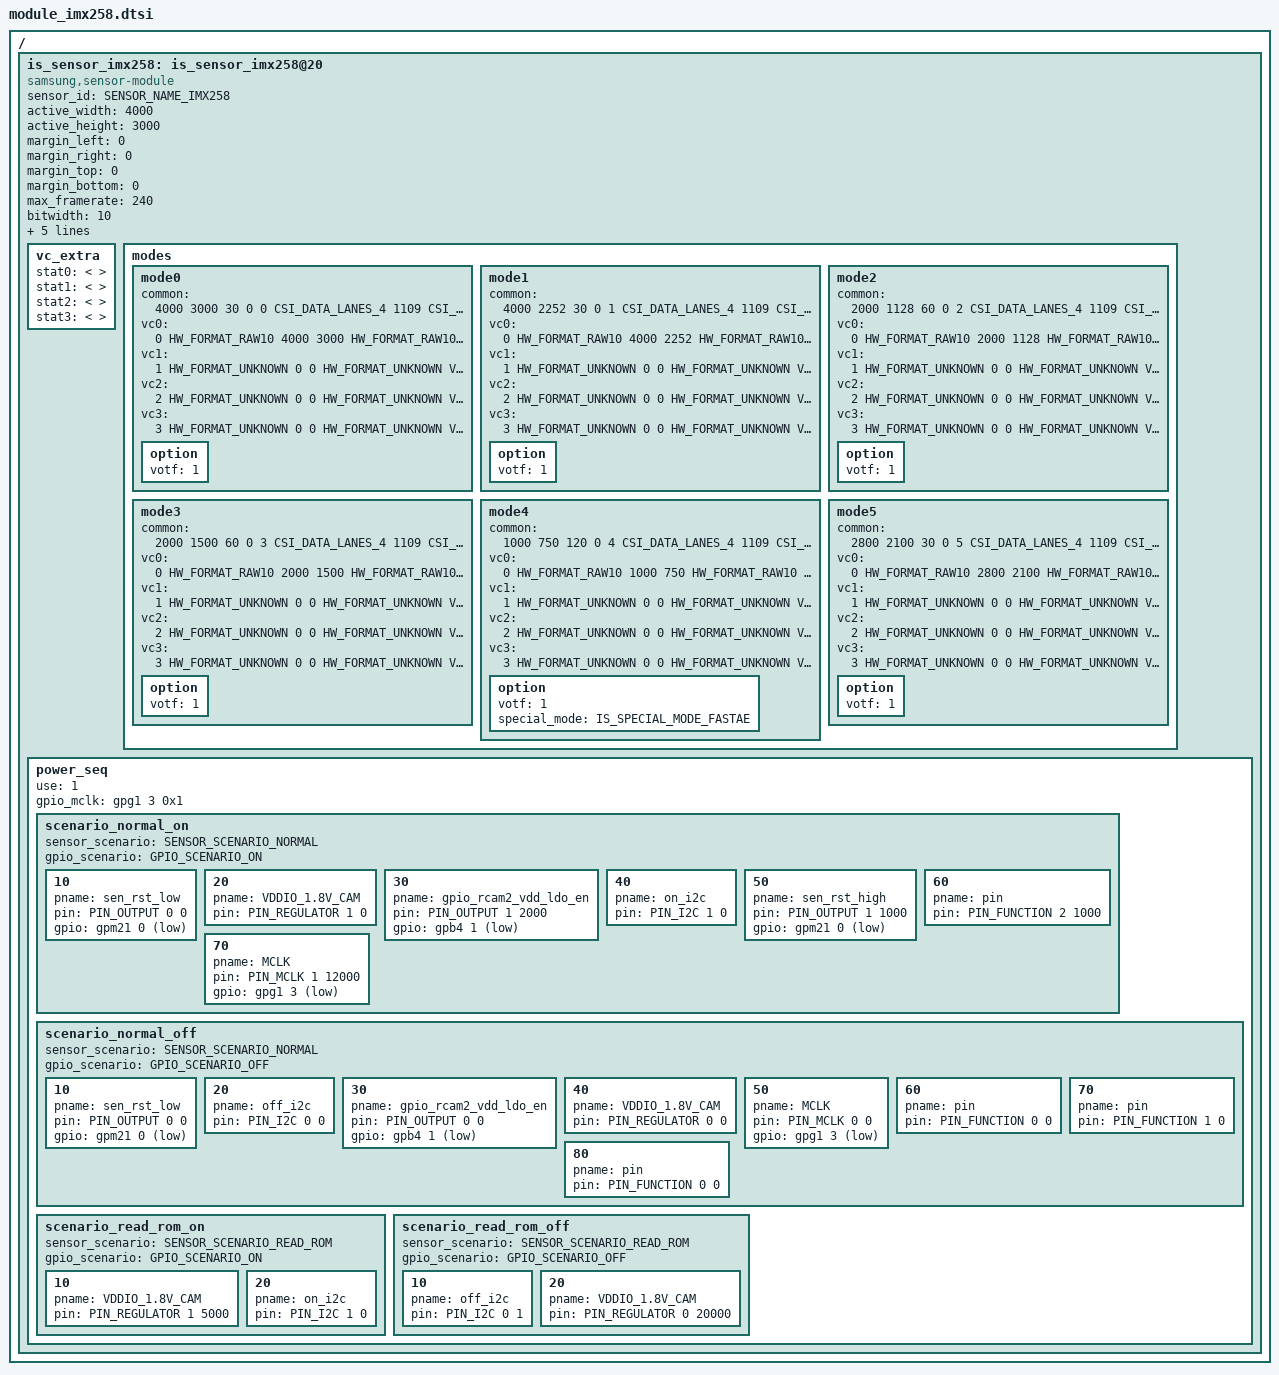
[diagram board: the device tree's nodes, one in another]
/*
 * SAMSUNG EXYNOSxxxx board camera device tree source
 *
 * Copyright (c) 2019 Samsung Electronics Co., Ltd.
 *		http://www.samsung.com
 *
 * This program is free software; you can redistribute it and/or modify
 * it under the terms of the GNU General Public License version 2 as
 * published by the Free Software Foundation.
 */

#include <dt-bindings/camera/exynos_is_dt.h>

/ {
	fragment@camera {
		target-path = "/";
		__overlay__ {
			is_sensor_imx258: is_sensor_imx258@20 {
				compatible = "samsung,sensor-module";

				/* common */
				sensor_id = <SENSOR_NAME_IMX258>;
				active_width = <4000>;
				active_height = <3000>;
				margin_left = <0>;
				margin_right = <0>;
				margin_top = <0>;
				margin_bottom = <0>;
				max_framerate = <240>;
				bitwidth = <10>;
				use_retention_mode = <SENSOR_RETENTION_UNSUPPORTED>;
				sensor_maker = "SONY";
				sensor_name = "IMX258";
				setfile_name = "setfile_imx258.bin";

				status = "okay";

				vc_extra {
					/* ex) statX = <stat_type, sensor_mode, max_width, max_height, max_element> */
					stat0 = </* not avaliable */>;	/* VC_BUF_DATA_TYPE_SENSOR_STAT1 */
					stat1 = </* not avaliable */>;	/* VC_BUF_DATA_TYPE_GENERAL_STAT1 */
					stat2 = </* not avaliable */>;	/* VC_BUF_DATA_TYPE_SENSOR_STAT2 */
					stat3 = </* not avaliable */>;	/* VC_BUF_DATA_TYPE_GENERAL_STAT2 */
				};

				/* sensor modes */
				modes {
					/* common = <width, height, fps, settle, mode, lane, speed, interleave, lrte, pd_mode> */
					/* vcX = <map, hwformat, width, height, hwformat, type, width, height> */
					mode0 {/* A-1 */
						common = <4000 3000 30 0 0 CSI_DATA_LANES_4 1109 CSI_MODE_VC_DT LRTE_DISABLE PD_NONE>;
						vc0 = </* in */ 0 HW_FORMAT_RAW10 4000 3000    /* out */ HW_FORMAT_RAW10 VC_NOTHING 4000 3000>;
						vc1 = </* in */ 1 HW_FORMAT_UNKNOWN 0 0        /* out */ HW_FORMAT_UNKNOWN VC_NOTHING 0 0>;
						vc2 = </* in */ 2 HW_FORMAT_UNKNOWN 0 0        /* out */ HW_FORMAT_UNKNOWN VC_NOTHING 0 0>;
						vc3 = </* in */ 3 HW_FORMAT_UNKNOWN 0 0        /* out */ HW_FORMAT_UNKNOWN VC_NOTHING 0 0>;
						option { votf = <1>; };
					};
					mode1 {/* N-1 */
						common = <4000 2252 30 0 1 CSI_DATA_LANES_4 1109 CSI_MODE_VC_DT LRTE_DISABLE PD_NONE>;
						vc0 = </* in */ 0 HW_FORMAT_RAW10 4000 2252    /* out */ HW_FORMAT_RAW10 VC_NOTHING 4000 2252>;
						vc1 = </* in */ 1 HW_FORMAT_UNKNOWN 0 0        /* out */ HW_FORMAT_UNKNOWN VC_NOTHING 0 0>;
						vc2 = </* in */ 2 HW_FORMAT_UNKNOWN 0 0        /* out */ HW_FORMAT_UNKNOWN VC_NOTHING 0 0>;
						vc3 = </* in */ 3 HW_FORMAT_UNKNOWN 0 0        /* out */ HW_FORMAT_UNKNOWN VC_NOTHING 0 0>;
						option { votf = <1>; };
					};
					mode2 {/* K-1 */
						common = <2000 1128 60 0 2 CSI_DATA_LANES_4 1109 CSI_MODE_VC_DT LRTE_DISABLE PD_NONE>;
						vc0 = </* in */ 0 HW_FORMAT_RAW10 2000 1128    /* out */ HW_FORMAT_RAW10 VC_NOTHING 2000 1128>;
						vc1 = </* in */ 1 HW_FORMAT_UNKNOWN 0 0        /* out */ HW_FORMAT_UNKNOWN VC_NOTHING 0 0>;
						vc2 = </* in */ 2 HW_FORMAT_UNKNOWN 0 0        /* out */ HW_FORMAT_UNKNOWN VC_NOTHING 0 0>;
						vc3 = </* in */ 3 HW_FORMAT_UNKNOWN 0 0        /* out */ HW_FORMAT_UNKNOWN VC_NOTHING 0 0>;
						option { votf = <1>; };
					};
					mode3 {/* J-1 */
						common = <2000 1500 60 0 3 CSI_DATA_LANES_4 1109 CSI_MODE_VC_DT LRTE_DISABLE PD_NONE>;
						vc0 = </* in */ 0 HW_FORMAT_RAW10 2000 1500    /* out */ HW_FORMAT_RAW10 VC_NOTHING 2000 1500>;
						vc1 = </* in */ 1 HW_FORMAT_UNKNOWN 0 0        /* out */ HW_FORMAT_UNKNOWN VC_NOTHING 0 0>;
						vc2 = </* in */ 2 HW_FORMAT_UNKNOWN 0 0        /* out */ HW_FORMAT_UNKNOWN VC_NOTHING 0 0>;
						vc3 = </* in */ 3 HW_FORMAT_UNKNOWN 0 0        /* out */ HW_FORMAT_UNKNOWN VC_NOTHING 0 0>;
						option { votf = <1>; };
					};
					mode4 {/* M-1 */
						common = <1000 750 120 0 4 CSI_DATA_LANES_4 1109 CSI_MODE_VC_DT LRTE_DISABLE PD_NONE>;
						vc0 = </* in */ 0 HW_FORMAT_RAW10 1000 750    /* out */ HW_FORMAT_RAW10 VC_NOTHING 1000 750>;
						vc1 = </* in */ 1 HW_FORMAT_UNKNOWN 0 0        /* out */ HW_FORMAT_UNKNOWN VC_NOTHING 0 0>;
						vc2 = </* in */ 2 HW_FORMAT_UNKNOWN 0 0        /* out */ HW_FORMAT_UNKNOWN VC_NOTHING 0 0>;
						vc3 = </* in */ 3 HW_FORMAT_UNKNOWN 0 0        /* out */ HW_FORMAT_UNKNOWN VC_NOTHING 0 0>;
						option { votf = <1>;  special_mode = <IS_SPECIAL_MODE_FASTAE>; };
					};
					mode5 {/* P-1 */
						common = <2800 2100 30 0 5 CSI_DATA_LANES_4 1109 CSI_MODE_VC_DT LRTE_DISABLE PD_NONE>;
						vc0 = </* in */ 0 HW_FORMAT_RAW10 2800 2100    /* out */ HW_FORMAT_RAW10 VC_NOTHING 2800 2100>;
						vc1 = </* in */ 1 HW_FORMAT_UNKNOWN 0 0        /* out */ HW_FORMAT_UNKNOWN VC_NOTHING 0 0>;
						vc2 = </* in */ 2 HW_FORMAT_UNKNOWN 0 0        /* out */ HW_FORMAT_UNKNOWN VC_NOTHING 0 0>;
						vc3 = </* in */ 3 HW_FORMAT_UNKNOWN 0 0        /* out */ HW_FORMAT_UNKNOWN VC_NOTHING 0 0>;
						option { votf = <1>; };
					};
				};

				power_seq {
					use = <1>;
					gpio_mclk = <&gpg1 3 0x1>;
					scenario_normal_on {
						sensor_scenario = <SENSOR_SCENARIO_NORMAL>;
						gpio_scenario = <GPIO_SCENARIO_ON>;
						/* A start node number should be over the 10 for reserved number 0~9. */
						/* pname = "name"; pin = <act value delay voltage>; gpio = <gpx# # 0x1>; */
						10 { pname = "sen_rst_low"; pin = <PIN_OUTPUT 0 0>; gpio = <&gpm21 0 0x1>; };
						20 { pname = "VDDIO_1.8V_CAM"; pin = <PIN_REGULATOR 1 0>; };
						30 { pname = "gpio_rcam2_vdd_ldo_en"; pin = <PIN_OUTPUT 1 2000>; gpio = <&gpb4 1 0x1>; };
						40 { pname = "on_i2c"; pin = <PIN_I2C 1 0>; };
						50 { pname = "sen_rst_high"; pin = <PIN_OUTPUT 1 1000>; gpio = <&gpm21 0 0x1>; };
						60 { pname = "pin"; pin = <PIN_FUNCTION 2 1000>; };
						70 { pname = "MCLK"; pin = <PIN_MCLK 1 12000>; gpio = <&gpg1 3 0x1>; };
					};

					scenario_normal_off {
						sensor_scenario = <SENSOR_SCENARIO_NORMAL>;
						gpio_scenario = <GPIO_SCENARIO_OFF>;
						/* A start node number should be over the 10 for reserved number 0~9. */
						/* pname = "name"; pin = <act value delay voltage>; gpio = <gpx# # 0x1>; */
						10 { pname = "sen_rst_low"; pin = <PIN_OUTPUT 0 0>; gpio = <&gpm21 0 0x1>; };
						20 { pname = "off_i2c"; pin = <PIN_I2C 0 0>; };
						30 { pname = "gpio_rcam2_vdd_ldo_en"; pin = <PIN_OUTPUT 0 0>; gpio = <&gpb4 1 0x1>; };
						40 { pname = "VDDIO_1.8V_CAM"; pin = <PIN_REGULATOR 0 0>; };
						50 { pname = "MCLK"; pin = <PIN_MCLK 0 0>; gpio = <&gpg1 3 0x1>; };
						60 { pname = "pin"; pin = <PIN_FUNCTION 0 0>; };
						70 { pname = "pin"; pin = <PIN_FUNCTION 1 0>; };
						80 { pname = "pin"; pin = <PIN_FUNCTION 0 0>; };
					};

					scenario_read_rom_on {
						sensor_scenario = <SENSOR_SCENARIO_READ_ROM>;
						gpio_scenario = <GPIO_SCENARIO_ON>;
						/* pname = "name"; pin = <act value delay voltage>; gpio = <gpx# # 0x1>; */
						10 { pname = "VDDIO_1.8V_CAM"; pin = <PIN_REGULATOR 1 5000>; };
						20 { pname = "on_i2c"; pin = <PIN_I2C 1 0>; };
					};

					scenario_read_rom_off {
						sensor_scenario = <SENSOR_SCENARIO_READ_ROM>;
						gpio_scenario = <GPIO_SCENARIO_OFF>;
						/* pname = "name"; pin = <act value delay voltage>; gpio = <gpx# # 0x1>; */
						10 { pname = "off_i2c"; pin = <PIN_I2C 0 1>; };
						20 { pname = "VDDIO_1.8V_CAM"; pin = <PIN_REGULATOR 0 20000>; };
					};
				};
			};
		}; /* end of __overlay__ */
	}; /* end of fragment */
}; /* end of root */
